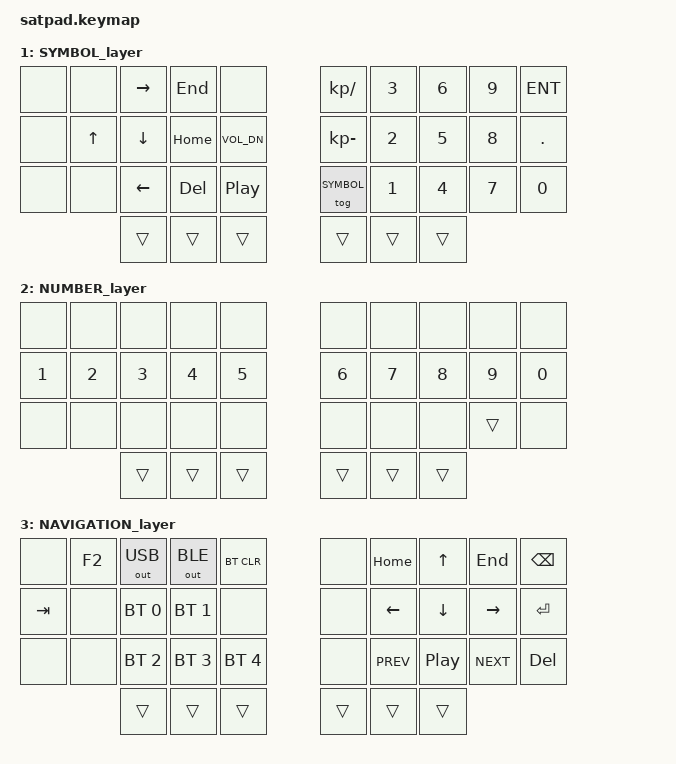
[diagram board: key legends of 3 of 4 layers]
/*/*
 * Copyright (c) 2022 The ZMK Contributors
 *
 * SPDX-License-Identifier: MIT
 */

#include <behaviors.dtsi>
#include <dt-bindings/zmk/keys.h>
#include <dt-bindings/zmk/bt.h>
#include <dt-bindings/zmk/outputs.h>

#define ALPHA       0
#define SYMBOL      1
#define NUMBER      2
#define NAVIGATION  3

&mt {
    flavor = "tap-preferred";
    tapping_term_ms = <180>;
};

/ {
    behaviors {
        tdq: tap_dance_qesc {
            compatible = "zmk,behavior-tap-dance";
            label = "tap_dance_qesc";
            #binding-cells = <0>;
            tapping-term-ms = <200>;
            bindings = <&kp Q>, <&kp ESC>;
        };

        bkt: tap_dance_bracket {
            compatible = "zmk,behavior-tap-dance";
            label = "tap_dance_bracket";
            #binding-cells = <0>;
            tapping-term-ms = <200>;
            bindings = <&kp LBKT>, <&kp RBKT>;
        };

        brc: tap_dance_brace {
            compatible = "zmk,behavior-tap-dance";
            label = "tap_dance_braces";
            #binding-cells = <0>;
            tapping-term-ms = <200>;
            bindings = <&kp LBRC>, <&kp RBRC>;
        };

        par: tap_dance_paren {
            compatible = "zmk,behavior-tap-dance";
            label = "tap_dance_paren";
            #binding-cells = <0>;
            tapping-term-ms = <200>;
            bindings = <&kp LPAR>, <&kp RPAR>;
        };

        thn: tap_dance_then {
            compatible = "zmk,behavior-tap-dance";
            label = "tap_dance_then";
            #binding-cells = <0>;
            tapping-term-ms = <200>;
            bindings = <&kp LT>, <&kp GT>;
        };

        skq: sticky_quick {
            compatible = "zmk,behavior-sticky-key";
            label = "sticky_quick";
            #binding-cells = <1>;
            bindings = <&kp>;
            release-after-ms = <1000>;
            quick-release;
        };

        hrm: homerow_mods {
           compatible = "zmk,behavior-hold-tap";
           label = "homerow_mods";
           #binding-cells = <2>;
           tapping-term-ms = <200>;
           quick-tap-ms = <0>;
           flavor = "tap-preferred";
           bindings = <&kp>, <&kp>;

        };
    };

    conditional_layers {
        compatible = "zmk,conditional-layers";
        tri_layer {
            if-layers = <SYMBOL NUMBER>;
            then-layer = <NAVIGATION>;
        };
    };

    keymap {
        compatible = "zmk,keymap";

        ALPHA_layer {
            bindings = <
                &kp F3    &kp F6       &kp F9       &kp F12       &kp C_MUTE     &kp KP_ MULTIPLY   &kp N3    &kp N6    &kp N9    &kp ENT
                &kp F2    &kp F5       &kp F8       &kp F11       &kp C_VOL_UP   &kp KP_ PLUS       &kp N2    &kp N5    &kp N8    &kp DOT
                &kp F1    &kp F4       &kp F7       &kp F10       &kp C_PP       &tog SYMBOL        &kp N1    &kp N4    &kp N7    &kp N0
                                &kp LCTRL   &sl SYMBOL &skq LSHIFT     &kp SPACE &lt NUMBER BSPC  &kp RET
            >;
        };

        SYMBOL_layer {
            bindings = <
                &none     &none      &kp RIGHT    &kp END    &none          &kp KP_DIVIDE  &kp N3     &kp N6    &kp N9    &kp ENT
                &none     &kp UP     &kp DOWN     &kp HOME   &kp C_VOL_DN   &kp KP_MINUS   &kp N2     &kp N5    &kp N8    &kp DOT
                &none     &none      &kp LEFT     &kp DEL    &kp C_PP       &tog SYMBOL    &kp N1     &kp N4    &kp N7    &kp N0
                                        &trans      &trans      &trans      &trans      &trans      &trans
            >;
        };

        NUMBER_layer {
            bindings = <
                &none       &none       &none       &none       &none       &none       &none       &none       &none       &none
                &kp N1      &kp N2      &kp N3      &kp N4      &kp N5      &kp N6      &kp N7      &kp N8      &kp N9      &kp N0
                &none       &none       &none       &none       &none       &none       &none       &none       &trans      &none
                                        &trans      &trans      &trans      &trans      &trans      &trans
            >;
        };

        NAVIGATION_layer {
            bindings = <
                &none           &kp F2          &out OUT_USB    &out OUT_BLE    &bt BT_CLR      &none       &kp HOME    &kp UP      &kp END     &kp BSPC 
                &kp TAB         &none           &bt BT_SEL 0    &bt BT_SEL 1          &none           &none       &kp LEFT    &kp DOWN    &kp RIGHT   &kp RET
                &none           &none           &bt BT_SEL 2    &bt BT_SEL 3    &bt BT_SEL 4    &none       &kp C_PREV  &kp C_PP    &kp C_NEXT  &kp DEL    
                                                &trans          &trans          &trans          &trans      &trans      &trans
            >;
        };
    };
};


